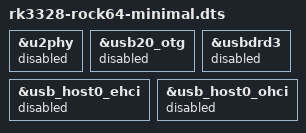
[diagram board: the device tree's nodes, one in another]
#include "rk3328-rock64.dts"

&u2phy {
	status = "disabled";
};

&usb20_otg {
	status = "disabled";
};

&usbdrd3 {
	status = "disabled";
};

&usb_host0_ehci {
	status = "disabled";
};

&usb_host0_ohci {
	status = "disabled";
};
